# R7FA0E107 register map
Vendor: Renesas Electronics Corporation; Series: RA0; File version: 1.10.00
CPU: CM23 r1p0, little endian, no MPU, no FPU, VTOR, 2 interrupt priority bits, 64 interrupts
Registers are 16-bit, read-write, reset 0x0 unless marked. A register's access mark holds for its fields unless they carry their own. Offsets are from the block's base; [hi:lo] are bit positions; {n}, {i} and the like mark numbered series.

## ICU — Interrupt Controller
Base 0x40006000
{0x0+i} IRQCR{i} (i=0..5) 8-bit — IRQ Control Register {i}
  [1:0] IRQMD — IRQi Detection Sense Select
0x100 NMICR 8-bit — NMI Pin Interrupt Control Register
  [0] NMIMD — NMI Detection Set
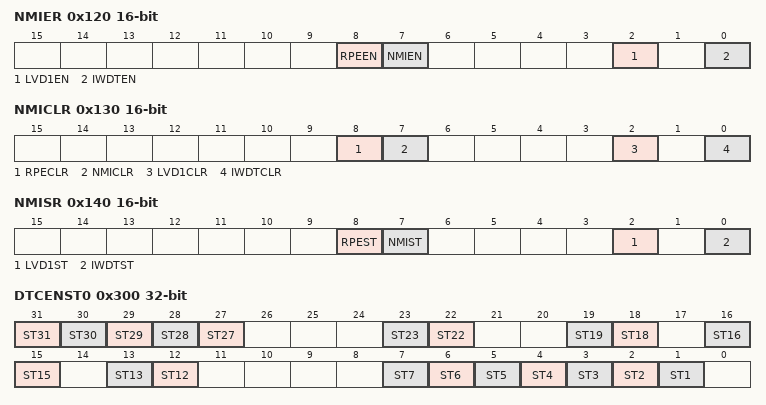
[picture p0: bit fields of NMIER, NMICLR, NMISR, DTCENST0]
0x120 NMIER — Non,maskable Interrupt Enable Register
  [8] RPEEN — SRAM Parity Error Interrupt Enable
  [7] NMIEN — NMI Pin Interrupt Enable
  [2] LVD1EN — Voltage Monitor 1 Interrupt Enable
  [0] IWDTEN — IWDT Underflow/Refresh Error Interrupt Enable
0x130 NMICLR — Non,maskable Interrupt Status Clear Register
  [8] RPECLR — SRAM Parity Error Interrupt Status Flag Clear
  [7] NMICLR — NMI Pin Interrupt Status Flag Clear
  [2] LVD1CLR — Voltage Monitor 1 Interrupt Status Flag Clear
  [0] IWDTCLR — IWDT Underflow/Refresh Error Interrupt Status Flag Clear
0x140 NMISR ro — Non,maskable Interrupt Status Register
  [8] RPEST — SRAM Parity Error Interrupt Status Flag
  [7] NMIST — NMI Pin Interrupt Status Flag
  [2] LVD1ST — Voltage Monitor 1 Interrupt Status Flag
  [0] IWDTST — IWDT Underflow/Refresh Error Interrupt Status Flag
0x300 DTCENST0 32-bit ro — DTC Enable Status Register 0
  [n] ST{n} (n=27..31) — DTC Enable Status by Event Number i
  [23] ST23 — DTC Enable Status by Event Number i
  [22] ST22 — DTC Enable Status by Event Number i
  [19] ST19 — DTC Enable Status by Event Number i
  [18] ST18 — DTC Enable Status by Event Number i
  [16] ST16 — DTC Enable Status by Event Number i
  [15] ST15 — DTC Enable Status by Event Number i
  [13] ST13 — DTC Enable Status by Event Number i
  [12] ST12 — DTC Enable Status by Event Number i
  [n] ST{n} (n=1..7) — DTC Enable Status by Event Number i
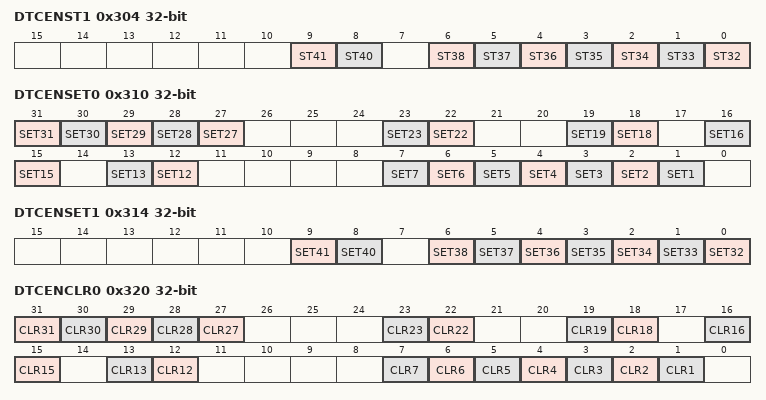
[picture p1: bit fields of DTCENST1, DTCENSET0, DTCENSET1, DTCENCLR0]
0x304 DTCENST1 32-bit ro — DTC Enable Status Register 1
  [9] ST41 — DTC Enable Status by Event Number i
  [8] ST40 — DTC Enable Status by Event Number i
  [n-32] ST{n} (n=32..38) — DTC Enable Status by Event Number i
0x310 DTCENSET0 32-bit — DTC Enable Set Register 0
  [n] SET{n} (n=27..31) — DTC Enable Set by Event Number i
  [23] SET23 — DTC Enable Set by Event Number i
  [22] SET22 — DTC Enable Set by Event Number i
  [19] SET19 — DTC Enable Set by Event Number i
  [18] SET18 — DTC Enable Set by Event Number i
  [16] SET16 — DTC Enable Set by Event Number i
  [15] SET15 — DTC Enable Set by Event Number i
  [13] SET13 — DTC Enable Set by Event Number i
  [12] SET12 — DTC Enable Set by Event Number i
  [n] SET{n} (n=1..7) — DTC Enable Set by Event Number i
0x314 DTCENSET1 32-bit — DTC Enable Set Register 1
  [9] SET41 — DTC Enable Set by Event Number i
  [8] SET40 — DTC Enable Set by Event Number i
  [n-32] SET{n} (n=32..38) — DTC Enable Set by Event Number i
0x320 DTCENCLR0 32-bit — DTC Enable Clear Register 0
  [n] CLR{n} (n=27..31) — DTC Enable Clear by Event Number i
  [23] CLR23 — DTC Enable Clear by Event Number i
  [22] CLR22 — DTC Enable Clear by Event Number i
  [19] CLR19 — DTC Enable Clear by Event Number i
  [18] CLR18 — DTC Enable Clear by Event Number i
  [16] CLR16 — DTC Enable Clear by Event Number i
  [15] CLR15 — DTC Enable Clear by Event Number i
  [13] CLR13 — DTC Enable Clear by Event Number i
  [12] CLR12 — DTC Enable Clear by Event Number i
  [n] CLR{n} (n=1..7) — DTC Enable Clear by Event Number i
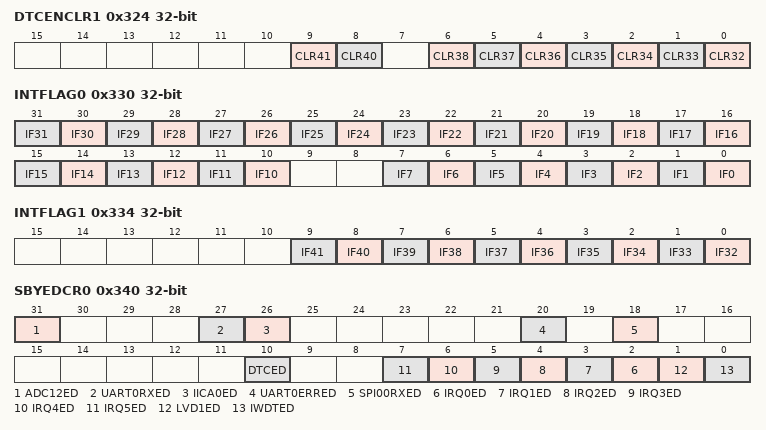
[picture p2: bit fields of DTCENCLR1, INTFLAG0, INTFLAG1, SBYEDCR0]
0x324 DTCENCLR1 32-bit — DTC Enable Clear Register 1
  [9] CLR41 — DTC Enable Clear by Event Number i
  [8] CLR40 — DTC Enable Clear by Event Number i
  [n-32] CLR{n} (n=32..38) — DTC Enable Clear by Event Number i
0x330 INTFLAG0 32-bit ro — Interrupt Request Flag Monitor Register 0
  [n] IF{n} (n=10..31) — Interrupt Request Flag Monitor
  [n] IF{n} (n=0..7) — Interrupt Request Flag Monitor
0x334 INTFLAG1 32-bit ro — Interrupt Request Flag Monitor Register 1
  [n-32] IF{n} (n=32..41) — Interrupt Request Flag Monitor
0x340 SBYEDCR0 32-bit — Software Standby/Snooze End Control Register 0
  [31] ADC12ED — End of A/D Conversion Interrupt Snooze Mode Returns Enable
  [27] UART0RXED — UART0 Reception Transfer End Interrupt Snooze Mode Returns Enable
  [26] IICA0ED — IICA0 Address Match Interrupt Software Standby/Snooze Mode Returns Enable
  [20] UART0ERRED — UART0 Reception Communication Error Occurrence Interrupt Snooze Mode Returns Enable
  [18] SPI00RXED — SPI00 Transfer End or Buffer Empty Interrupt Snooze Mode Returns Enable
  [10] DTCED — DTC Transfer Complete Interrupt Snooze Mode Returns Enable
  [n+2] IRQ{n}ED (n=0..5)
  [1] LVD1ED — LVD1 Interrupt Software Standby/Snooze Mode Returns Enable
  [0] IWDTED — IWDT Interrupt Software Standby/Snooze Mode Returns Enable
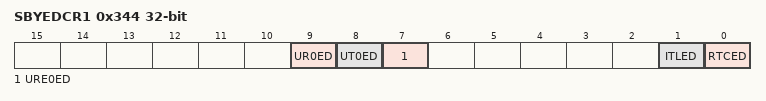
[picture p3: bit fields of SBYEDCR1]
0x344 SBYEDCR1 32-bit — Software Standby/Snooze End Control Register 1
  [9] UR0ED — UARTA0 Reception Transfer End Interrupt Software Standby/Snooze Mode Returns Enable
  [8] UT0ED — UARTA0 Transmission Transfer End or Buffer Empty Interrupt Software Standby/Snooze Mode Returns Enable
  [7] URE0ED — UARTA0 Reception Communication Error Interrupt Software Standby/Snooze Mode Returns Enable
  [1] ITLED — Interval Signal of 32-bit Interval Timer Interrupt Software Standby/Snooze Mode Returns Enable
  [0] RTCED — RTC Interrupt Software Standby/Snooze Mode Returns Enable
